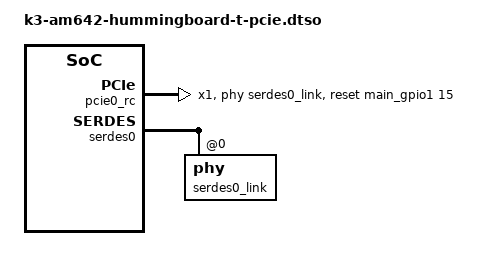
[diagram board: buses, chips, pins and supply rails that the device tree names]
// SPDX-License-Identifier: GPL-2.0+
/*
 * Copyright (C) 2023 Josua Mayer <josua@solid-run.com>
 *
 * Overlay for SolidRun AM642 HummingBoard-T to enable PCI-E.
 */

/dts-v1/;
/plugin/;

#include <dt-bindings/gpio/gpio.h>
#include <dt-bindings/phy/phy.h>

#include "k3-serdes.h"

&pcie0_rc {
	pinctrl-names = "default";
	pinctrl-0 = <&pcie0_default_pins>;
	reset-gpios = <&main_gpio1 15 GPIO_ACTIVE_HIGH>;
	phys = <&serdes0_link>;
	phy-names = "pcie-phy";
	num-lanes = <1>;
	status = "okay";
};

&serdes0 {
	#address-cells = <1>;
	#size-cells = <0>;

	serdes0_link: phy@0 {
		reg = <0>;
		cdns,num-lanes = <1>;
		cdns,phy-type = <PHY_TYPE_PCIE>;
		#phy-cells = <0>;
		resets = <&serdes_wiz0 1>;
	};
};

&serdes_ln_ctrl {
	idle-states = <AM64_SERDES0_LANE0_PCIE0>;
};

&serdes_mux {
	idle-state = <1>;
};
